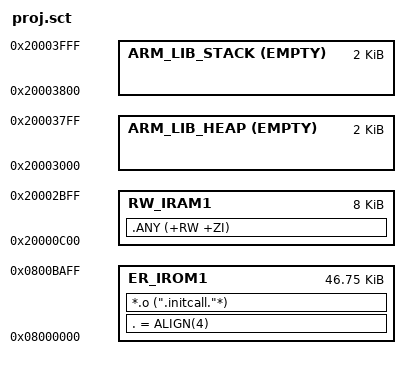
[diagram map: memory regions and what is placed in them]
; *************************************************************
; *** Scatter-Loading Description File generated by uVision ***
; *************************************************************
LR_IROM1 0x08000000 0x00010000  
{    ; load region size_region
  ER_IROM1 0x08000000 0xBB00  
  {  ; load address = execution address
   *.o (RESET, +First)
   *(InRoot$$Sections)
  	.ANY (+RO)
  }  

  MY_REGION+0{     ;自定义函数存储位置，地址及大小仅作说明
   . = ALIGN(4);          
   *.o (".initcall."*)   
  }
  
  RW_IRAM1 0x20000C00 0x00002000  ; RW data Total=45k;here use 40k;
  {  
   .ANY (+RW +ZI)
  }

  ARM_LIB_HEAP  0x20003000 EMPTY  0x00000800   {} ;Heap use 2k
  ARM_LIB_STACK 0x20004000 EMPTY -0x00000800   {} ;Stack use 2k

}


